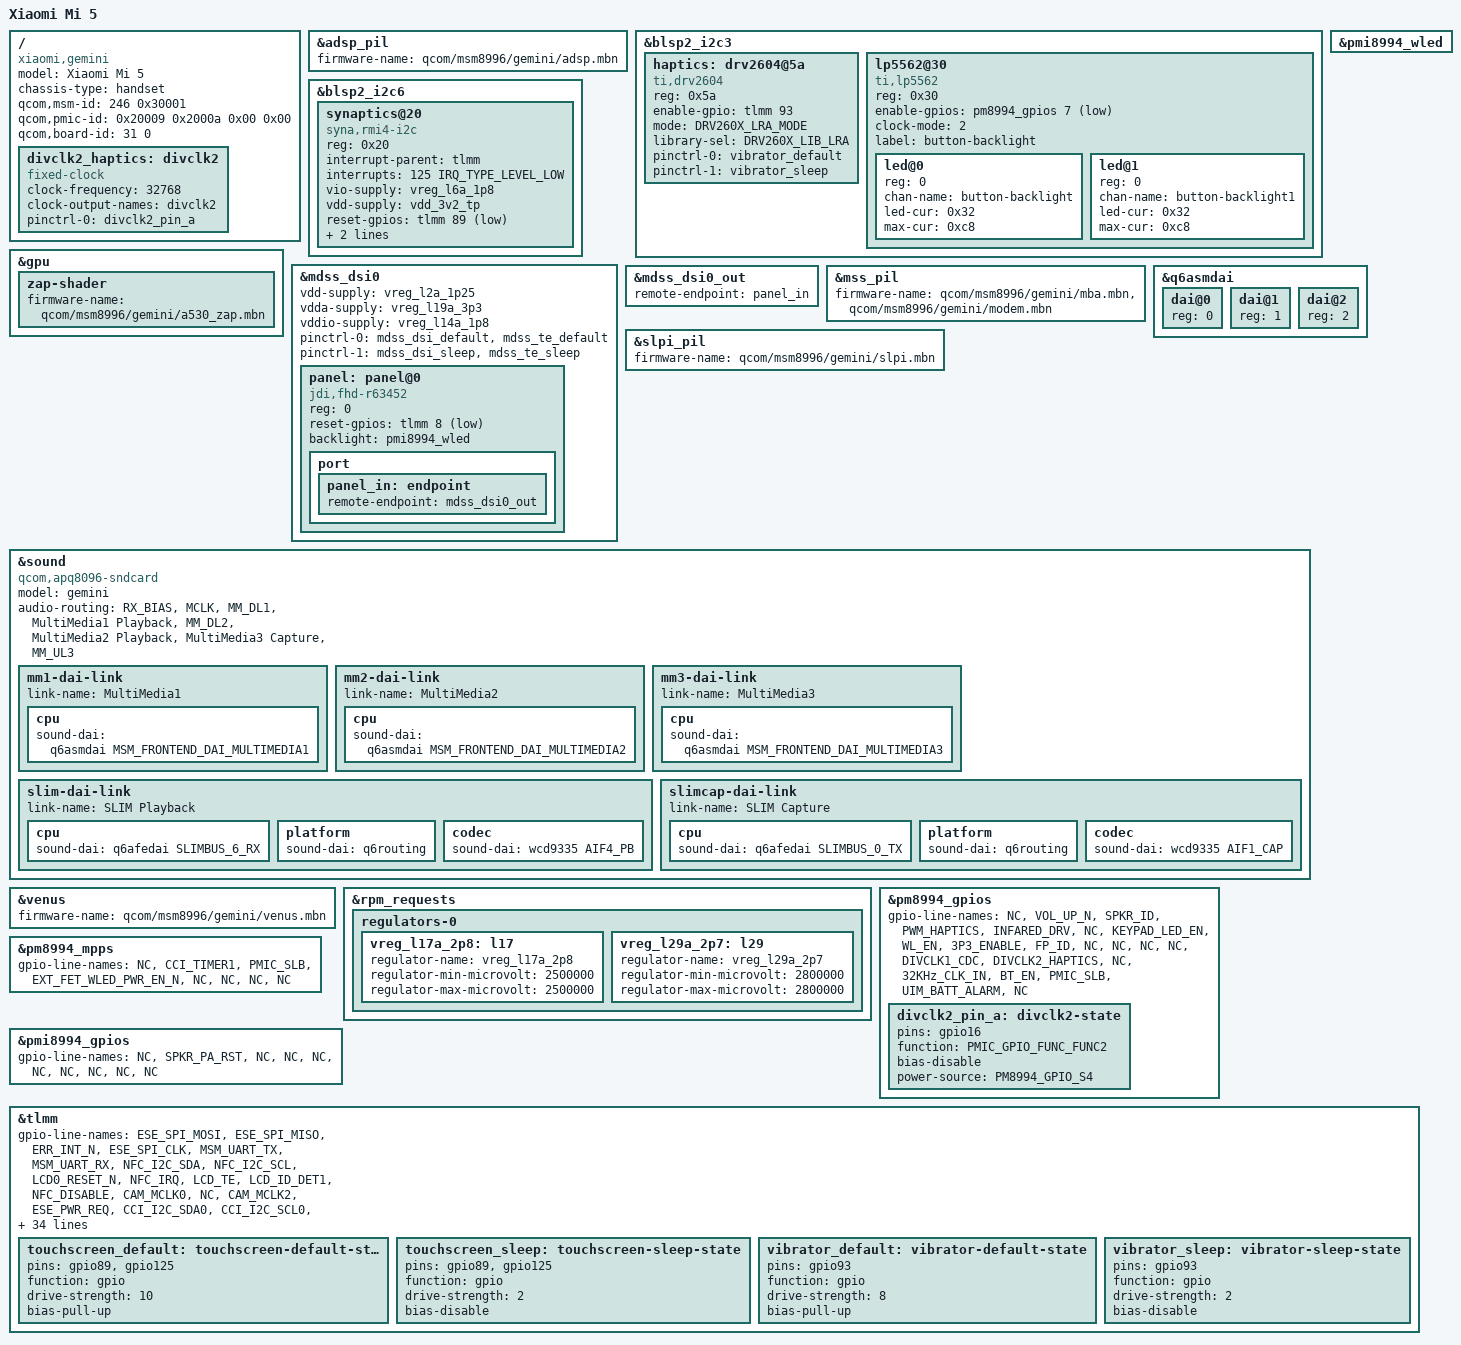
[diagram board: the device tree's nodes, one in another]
/dts-v1/;
#include "msm8996.dtsi"
#include "msm8996-xiaomi-common.dtsi"
#include <dt-bindings/sound/qcom,q6afe.h>
#include <dt-bindings/sound/qcom,q6asm.h>
#include <dt-bindings/sound/qcom,wcd9335.h>
#include <dt-bindings/input/ti-drv260x.h>
/ {
	model = "Xiaomi Mi 5";
	compatible = "xiaomi,gemini", "qcom,msm8996";
	chassis-type = "handset";
	qcom,msm-id = <246 0x30001>;
	qcom,pmic-id = <0x20009 0x2000a 0x00 0x00>;
	qcom,board-id = <31 0>;
	divclk2_haptics: divclk2 {
		compatible = "fixed-clock";
		#clock-cells = <0>;
		clock-frequency = <32768>;
		clock-output-names = "divclk2";
		pinctrl-names = "default";
		pinctrl-0 = <&divclk2_pin_a>;
	};
};
&adsp_pil {
	firmware-name = "qcom/msm8996/gemini/adsp.mbn";
};
&blsp2_i2c3 {
	haptics: drv2604@5a {
		compatible = "ti,drv2604";
		reg = <0x5a>;
		enable-gpio = <&tlmm 93 0x00>;
		mode = <DRV260X_LRA_MODE>;
		library-sel = <DRV260X_LIB_LRA>;
		pinctrl-names = "default","sleep";
		pinctrl-0 = <&vibrator_default>;
		pinctrl-1 = <&vibrator_sleep>;
	};
	lp5562@30 {
		compatible = "ti,lp5562";
		reg = <0x30>;
		#address-cells = <1>;
		#size-cells = <0>;
		enable-gpios = <&pm8994_gpios 7 1>;
		clock-mode = /bits/8 <2>;
		label = "button-backlight";
		led@0 {
			reg = <0>;
			chan-name = "button-backlight";
			led-cur = /bits/ 8 <0x32>;
			max-cur = /bits/ 8 <0xc8>;
		};
		led@1 {
			reg = <0>;
			chan-name = "button-backlight1";
			led-cur = /bits/ 8 <0x32>;
			max-cur = /bits/ 8 <0xc8>;
		};
	};
};
&blsp2_i2c6 {
	synaptics@20 {
		compatible = "syna,rmi4-i2c";
		reg = <0x20>;
		#address-cells = <1>;
		#size-cells = <0>;
		interrupt-parent = <&tlmm>;
		interrupts = <125 IRQ_TYPE_LEVEL_LOW>;
		vio-supply = <&vreg_l6a_1p8>;
		vdd-supply = <&vdd_3v2_tp>;
		reset-gpios = <&tlmm 89 GPIO_ACTIVE_LOW>;
		pinctrl-names = "default", "sleep";
		pinctrl-0 = <&touchscreen_default>;
		pinctrl-1 = <&touchscreen_sleep>;
	};
};
&gpu {
	zap-shader {
		firmware-name = "qcom/msm8996/gemini/a530_zap.mbn";
	};
};
&mdss_dsi0 {
	status = "okay";
	vdd-supply = <&vreg_l2a_1p25>;
	vdda-supply = <&vreg_l19a_3p3>;
	vddio-supply = <&vreg_l14a_1p8>;
	pinctrl-names = "default", "sleep";
	pinctrl-0 = <&mdss_dsi_default &mdss_te_default>;
	pinctrl-1 = <&mdss_dsi_sleep &mdss_te_sleep>;
	panel: panel@0 {
		compatible = "jdi,fhd-r63452";
		reg = <0>;
		reset-gpios = <&tlmm 8 GPIO_ACTIVE_LOW>;
		backlight = <&pmi8994_wled>;
		port {
			panel_in: endpoint {
				remote-endpoint = <&mdss_dsi0_out>;
			};
		};
	};
};
&mdss_dsi0_out {
	remote-endpoint = <&panel_in>;
};
&pmi8994_wled {
	status = "okay";
};
&mss_pil {
	firmware-name = "qcom/msm8996/gemini/mba.mbn",
			"qcom/msm8996/gemini/modem.mbn";
};
&q6asmdai {
	dai@0 {
		reg = <0>;
	};
	dai@1 {
		reg = <1>;
	};
	dai@2 {
		reg = <2>;
	};
};
&slpi_pil {
	firmware-name = "qcom/msm8996/gemini/slpi.mbn";
};
&sound {
	compatible = "qcom,apq8096-sndcard";
	model = "gemini";
	audio-routing = "RX_BIAS", "MCLK",
		"MM_DL1",  "MultiMedia1 Playback",
		"MM_DL2",  "MultiMedia2 Playback",
		"MultiMedia3 Capture", "MM_UL3";
	mm1-dai-link {
		link-name = "MultiMedia1";
		cpu {
			sound-dai = <&q6asmdai MSM_FRONTEND_DAI_MULTIMEDIA1>;
		};
	};
	mm2-dai-link {
		link-name = "MultiMedia2";
		cpu {
			sound-dai = <&q6asmdai MSM_FRONTEND_DAI_MULTIMEDIA2>;
		};
	};
	mm3-dai-link {
		link-name = "MultiMedia3";
		cpu {
			sound-dai = <&q6asmdai MSM_FRONTEND_DAI_MULTIMEDIA3>;
		};
	};
	slim-dai-link {
		link-name = "SLIM Playback";
		cpu {
			sound-dai = <&q6afedai SLIMBUS_6_RX>;
		};
		platform {
			sound-dai = <&q6routing>;
		};
		codec {
			sound-dai = <&wcd9335 AIF4_PB>;
		};
	};
	slimcap-dai-link {
		link-name = "SLIM Capture";
		cpu {
			sound-dai = <&q6afedai SLIMBUS_0_TX>;
		};
		platform {
			sound-dai = <&q6routing>;
		};
		codec {
			sound-dai = <&wcd9335 AIF1_CAP>;
		};
	};
};
&venus {
	firmware-name = "qcom/msm8996/gemini/venus.mbn";
};
&rpm_requests {
	regulators-0 {
		vreg_l17a_2p8: l17 {
			regulator-name = "vreg_l17a_2p8";
			regulator-min-microvolt = <2500000>;
			regulator-max-microvolt = <2500000>;
		};
		vreg_l29a_2p7: l29 {
			regulator-name = "vreg_l29a_2p7";
			regulator-min-microvolt = <2800000>;
			regulator-max-microvolt = <2800000>;
		};
	};
};
&pm8994_gpios {
	gpio-line-names =
		"NC",			 
		"VOL_UP_N",		 
		"SPKR_ID",		 
		"PWM_HAPTICS",		 
		"INFARED_DRV",		 
		"NC",			 
		"KEYPAD_LED_EN",	 
		"WL_EN",		 
		"3P3_ENABLE",		 
		"FP_ID",		 
		"NC",			 
		"NC",			 
		"NC",			 
		"NC",			 
		"DIVCLK1_CDC",		 
		"DIVCLK2_HAPTICS",	 
		"NC",			 
		"32KHz_CLK_IN",		 
		"BT_EN",		 
		"PMIC_SLB",		 
		"UIM_BATT_ALARM",	 
		"NC";			 
	divclk2_pin_a: divclk2-state {
		pins = "gpio16";
		function = PMIC_GPIO_FUNC_FUNC2;
		bias-disable;
		power-source = <PM8994_GPIO_S4>;
	};
};
&pm8994_mpps {
	gpio-line-names =
		"NC",			 
		"CCI_TIMER1",		 
		"PMIC_SLB",		 
		"EXT_FET_WLED_PWR_EN_N", 
		"NC",			 
		"NC",			 
		"NC",			 
		"NC";			 
};
&pmi8994_gpios {
	gpio-line-names =
		"NC",			 
		"SPKR_PA_RST",		 
		"NC",			 
		"NC",			 
		"NC",			 
		"NC",			 
		"NC",			 
		"NC",			 
		"NC",			 
		"NC";			 
};
&tlmm {
	gpio-line-names =
		"ESE_SPI_MOSI",		 
		"ESE_SPI_MISO",		 
		"ERR_INT_N",		 
		"ESE_SPI_CLK",		 
		"MSM_UART_TX",		 
		"MSM_UART_RX",		 
		"NFC_I2C_SDA",		 
		"NFC_I2C_SCL",		 
		"LCD0_RESET_N",		 
		"NFC_IRQ",		 
		"LCD_TE",		 
		"LCD_ID_DET1",		 
		"NFC_DISABLE",		 
		"CAM_MCLK0",		 
		"NC",			 
		"CAM_MCLK2",		 
		"ESE_PWR_REQ",		 
		"CCI_I2C_SDA0",		 
		"CCI_I2C_SCL0",		 
		"CCI_I2C_SDA1",		 
		"CCI_I2C_SCL1",		 
		"NFC_DWL_REQ",		 
		"CCI_TIMER1",		 
		"WEBCAM1_RESET_N",	 
		"ESE_IRQ",		 
		"NC",			 
		"WEBCAM1_STANDBY",	 
		"NC",			 
		"NC",			 
		"NC",			 
		"CAM1_RST_N",		 
		"NC",			 
		"NC",			 
		"NC",			 
		"FP_DOME_SW",		 
		"PCI_E0_RST_N",		 
		"PCI_E0_CLKREQ_N",	 
		"PCI_E0_WAKE",		 
		"FM_INT_N",		 
		"FM_RESET_N",		 
		"NC",			 
		"QCA_UART_TXD",		 
		"QCA_UART_RXD",		 
		"QCA_UART_CTS",		 
		"QCA_UART_RTS",		 
		"MAWC_UART_TX",		 
		"MAWC_UART_RX",		 
		"NC",			 
		"NC",			 
		"AUDIO_SWITCH_EN",	 
		"FP_SPI_RST",		 
		"TYPEC_I2C_SDA",	 
		"TYPEC_I2C_SCL",	 
		"CODEC_INT2_N",		 
		"CODEC_INT1_N",		 
		"APPS_I2C7_SDA",	 
		"APPS_I2C7_SCL",	 
		"FORCE_USB_BOOT",	 
		"SPKR_I2S_BCK",		 
		"SPKR_I2S_WS",		 
		"SPKR_I2S_DOUT",	 
		"SPKR_I2S_DIN",		 
		"ESE_RSTN",		 
		"TYPEC_INT",		 
		"CODEC_RESET_N",	 
		"PCM_CLK",		 
		"PCM_SYNC",		 
		"PCM_DIN",		 
		"PCM_DOUT",		 
		"HIFI_CLK",		 
		"SLIMBUS_CLK",		 
		"SLIMBUS_DATA0",	 
		"SLIMBUS_DATA1",	 
		"LDO_5V_IN_EN",		 
		"NC",			 
		"FM_I2S_CLK",		 
		"FM_I2S_SYNC",		 
		"FM_I2S_DATA",		 
		"FM_STATUS",		 
		"NC",			 
		"SENSOR_RESET_N",	 
		"FP_SPI_MOSI",		 
		"FP_SPI_MISO",		 
		"FP_SPI_CS_N",		 
		"FP_SPI_CLK",		 
		"NC",			 
		"CAM_VDD_1P05_EN",	 
		"MSM_TS_I2C_SDA",	 
		"MSM_TS_I2C_SCL",	 
		"TS_RESOUT_N",		 
		"ESE_SPI_CS_N",		 
		"NC",			 
		"NC",			 
		"HAPTICS_EN",		 
		"NC",			 
		"NC",			 
		"NC",			 
		"NC",			 
		"GRFC_1",		 
		"NC",			 
		"GRFC_3",		 
		"GRFC_4",		 
		"NC",			 
		"NC",			 
		"GRFC_7",		 
		"UIM2_DATA",		 
		"UIM2_CLK",		 
		"UIM2_RESET",		 
		"UIM2_PRESENT",		 
		"UIM1_DATA",		 
		"UIM1_CLK",		 
		"UIM1_RESET",		 
		"UIM1_PRESENT",		 
		"UIM_BATT_ALARM",	 
		"GRFC_8",		 
		"GRFC_9",		 
		"TX_GTR_THRES",		 
		"ACCEL_INT",		 
		"GYRO_INT",		 
		"COMPASS_INT",		 
		"PROXIMITY_INT_N",	 
		"FP_IRQ",		 
		"NC",			 
		"HALL_INTR2",		 
		"HALL_INTR1",		 
		"TS_INT_N",		 
		"NC",			 
		"GRFC_11",		 
		"NC",			 
		"EXT_GPS_LNA_EN",	 
		"NC",			 
		"NC",			 
		"NC",			 
		"GRFC_14",		 
		"GSM_TX2_PHASE_D",	 
		"NC",			 
		"NC",			 
		"RFFE3_DATA",		 
		"RFFE3_CLK",		 
		"NC",			 
		"NC",			 
		"RFFE5_DATA",		 
		"RFFE5_CLK",		 
		"NC",			 
		"COEX_UART_TX",		 
		"COEX_UART_RX",		 
		"RFFE2_DATA",		 
		"RFFE2_CLK",		 
		"RFFE1_DATA",		 
		"RFFE1_CLK";		 
	touchscreen_default: touchscreen-default-state {
		pins = "gpio89", "gpio125";
		function = "gpio";
		drive-strength = <10>;
		bias-pull-up;
	};
	touchscreen_sleep: touchscreen-sleep-state {
		pins = "gpio89", "gpio125";
		function = "gpio";
		drive-strength = <2>;
		bias-disable;
	};
	vibrator_default: vibrator-default-state {
		pins = "gpio93";
		function = "gpio";
		drive-strength = <8>;
		bias-pull-up;
	};
	vibrator_sleep: vibrator-sleep-state {
		pins = "gpio93";
		function = "gpio";
		drive-strength = <2>;
		bias-disable;
	};
};
